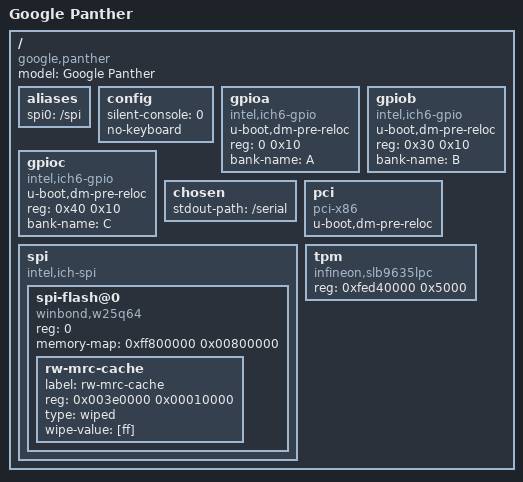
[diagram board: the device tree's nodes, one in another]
/dts-v1/;

/include/ "skeleton.dtsi"
/include/ "serial.dtsi"
/include/ "rtc.dtsi"

/ {
	model = "Google Panther";
	compatible = "google,panther", "intel,haswell";

	aliases {
		spi0 = "/spi";
	};

	config {
		silent-console = <0>;
		no-keyboard;
	};

	gpioa {
		compatible = "intel,ich6-gpio";
		u-boot,dm-pre-reloc;
		reg = <0 0x10>;
		bank-name = "A";
	};

	gpiob {
		compatible = "intel,ich6-gpio";
		u-boot,dm-pre-reloc;
		reg = <0x30 0x10>;
		bank-name = "B";
	};

	gpioc {
		compatible = "intel,ich6-gpio";
		u-boot,dm-pre-reloc;
		reg = <0x40 0x10>;
		bank-name = "C";
	};

	chosen {
		stdout-path = "/serial";
	};

	pci {
		compatible = "pci-x86";
		#address-cells = <3>;
		#size-cells = <2>;
		u-boot,dm-pre-reloc;
		ranges = <0x02000000 0x0 0xe0000000 0xe0000000 0 0x10000000
			0x42000000 0x0 0xd0000000 0xd0000000 0 0x10000000
			0x01000000 0x0 0x1000 0x1000 0 0xf000>;
	};

	spi {
		#address-cells = <1>;
		#size-cells = <0>;
		compatible = "intel,ich-spi";
		spi-flash@0 {
			#size-cells = <1>;
			#address-cells = <1>;
			reg = <0>;
			compatible = "winbond,w25q64", "spi-flash";
			memory-map = <0xff800000 0x00800000>;
			rw-mrc-cache {
				label = "rw-mrc-cache";
				/* Alignment: 4k (for updating) */
				reg = <0x003e0000 0x00010000>;
				type = "wiped";
				wipe-value = [ff];
			};
		};
	};

	tpm {
		reg = <0xfed40000 0x5000>;
		compatible = "infineon,slb9635lpc";
	};

};
